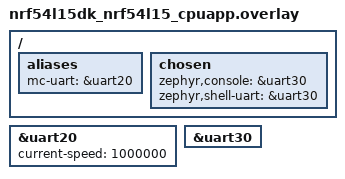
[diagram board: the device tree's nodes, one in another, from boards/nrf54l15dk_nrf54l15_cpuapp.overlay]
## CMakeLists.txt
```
# Copyright (c) 2026 Mahdi Sahebi
# SPDX-License-Identifier: Apache-2.0

cmake_minimum_required(VERSION 3.28.0)
find_package(Zephyr REQUIRED HINTS $ENV{ZEPHYR_BASE})
project(mc_uart_communication)

set(MICRO_CORE_ROOT "" CACHE PATH "Path to the micro_core source tree")
if(NOT EXISTS "${MICRO_CORE_ROOT}/src/io/communication/mc_communication.c")
  message(FATAL_ERROR "Set MICRO_CORE_ROOT to the micro_core source tree")
endif()

target_sources(app PRIVATE
  src/main.c
  src/mc_crc.c
  src/zephyr_time.c
  "${MICRO_CORE_ROOT}/src/io/communication/mc_communication.c"
  "${MICRO_CORE_ROOT}/src/io/communication/mc_frame.c"
  "${MICRO_CORE_ROOT}/src/io/communication/mc_io.c"
  "${MICRO_CORE_ROOT}/src/io/communication/mc_protocol.c"
  "${MICRO_CORE_ROOT}/src/io/communication/mc_window_pool.c"
)

target_include_directories(app PRIVATE
  "${MICRO_CORE_ROOT}/include"
  "${MICRO_CORE_ROOT}/src/io/communication"
  "${CMAKE_CURRENT_LIST_DIR}/include"
)
```

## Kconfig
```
# Copyright The Zephyr Project Contributors
# SPDX-License-Identifier: Apache-2.0

mainmenu "MC UART sample"

source "Kconfig.zephyr"

choice MC_UART_ROLE
	prompt "MC UART role"
	default MC_UART_SENDER
	help
	  Select whether this board transmits or receives the MC UART test
	  sequence. Build the same application with a different role on the
	  second board.

config MC_UART_SENDER
	bool "Sender"
	help
	  Send the MC message and signal test sequence.

config MC_UART_RECEIVER
	bool "Receiver"
	help
	  Receive and validate the MC message and signal test sequence.

endchoice
```

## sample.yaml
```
sample:
  name: Micro Core UART communication test
  description: Two-board UART transport for the micro_core communication suite
tests:
  sample.mc.uart.sender:
    build_only: true
    skip: true
    extra_args: CONF_FILE=prj_sender.conf
    platform_allow:
      - nrf54l15dk/nrf54l15/cpuapp
  sample.mc.uart.receiver:
    build_only: true
    skip: true
    extra_args: CONF_FILE=prj_receiver.conf
    platform_allow:
      - nrf54l15dk/nrf54l15/cpuapp
```

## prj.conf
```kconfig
CONFIG_MC=y
CONFIG_MC_COMM=y
CONFIG_MC_MSG=y
CONFIG_SERIAL=y
CONFIG_UART_INTERRUPT_DRIVEN=n
CONFIG_PRINTK=y
CONFIG_MC_UART_SENDER=y
```

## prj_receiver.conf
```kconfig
# SPDX-FileCopyrightText: Copyright The Zephyr Project Contributors
# SPDX-License-Identifier: Apache-2.0

CONFIG_SERIAL=y
CONFIG_RING_BUFFER_LARGE=y
CONFIG_UART_INTERRUPT_DRIVEN=y
CONFIG_PRINTK=y
CONFIG_CRC=y
CONFIG_CBPRINTF_FP_SUPPORT=y
CONFIG_MAIN_STACK_SIZE=8192
CONFIG_MC_UART_RECEIVER=y
```

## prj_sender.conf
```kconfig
# SPDX-FileCopyrightText: Copyright The Zephyr Project Contributors
# SPDX-License-Identifier: Apache-2.0

CONFIG_SERIAL=y
CONFIG_RING_BUFFER_LARGE=y
CONFIG_UART_INTERRUPT_DRIVEN=y
CONFIG_PRINTK=y
CONFIG_CRC=y
CONFIG_CBPRINTF_FP_SUPPORT=y
CONFIG_MAIN_STACK_SIZE=8192
CONFIG_MC_UART_SENDER=y
```

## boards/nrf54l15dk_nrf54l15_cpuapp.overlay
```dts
/*
 * SPDX-FileCopyrightText: Copyright The Zephyr Project Contributors
 * SPDX-License-Identifier: Apache-2.0
 */

/* Use UART20/Serial Port 1 for the protocol and UART30/Serial Port 0 as console. */
/ {
	aliases {
		mc-uart = &uart20;
	};

	chosen {
		zephyr,console = &uart30;
		zephyr,shell-uart = &uart30;
	};
};

&uart20 {
	current-speed = <1000000>;
};

&uart30 {
	status = "okay";
};
```

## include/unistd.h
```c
/*
 * Copyright (c) 2026 Mahdi Sahebi
 *
 * SPDX-License-Identifier: Apache-2.0
 */

#ifndef MICRO_CORE_ZEPHYR_UNISTD_H_
#define MICRO_CORE_ZEPHYR_UNISTD_H_

int usleep(unsigned int usec);

#endif
```

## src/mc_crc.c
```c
/*
 * Copyright (c) 2026 Mahdi Sahebi
 *
 * SPDX-License-Identifier: Apache-2.0
 */

#include <zephyr/sys/crc.h>

#include "alg/algorithm.h"

mc_u32 mc_alg_crc16_ccitt(mc_buffer buffer)
{
	if (mc_buffer_is_null(buffer)) {
		return mc_u32(0U, MC_ERR_INVALID_ARGUMENT);
	}

	return mc_u32(crc16_itu_t(0xffffU, (const uint8_t *)buffer.data,
				  buffer.capacity * buffer.data_size), MC_SUCCESS);
}
```

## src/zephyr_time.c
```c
/*
 * Copyright (c) 2026 Mahdi Sahebi
 *
 * SPDX-License-Identifier: Apache-2.0
 */

#include <zephyr/kernel.h>

#include "core/time.h"

mc_time_t mc_now_u(void)
{
	return k_cyc_to_us_floor64(k_cycle_get_64());
}

mc_time_t mc_now_m(void)
{
	return (mc_time_t)k_uptime_get();
}

mc_time_t mc_now_s(void)
{
	return mc_now_m() / 1000U;
}

mc_time_t mc_now(void)
{
	return k_cyc_to_ns_floor64(k_cycle_get_64());
}

int usleep(unsigned int usec)
{
	k_usleep(usec);
	return 0;
}
```
